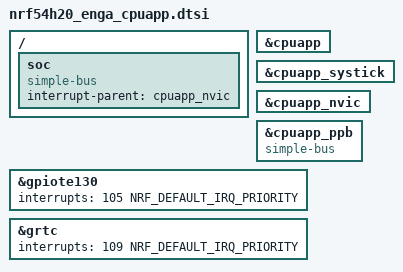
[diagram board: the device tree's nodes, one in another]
/*
 * Copyright (c) 2024 Nordic Semiconductor ASA
 *
 * SPDX-License-Identifier: Apache-2.0
 */

#include <nordic/nrf54h20_enga.dtsi>

cpu: &cpuapp {};
systick: &cpuapp_systick {};
nvic: &cpuapp_nvic {};

/delete-node/ &cpuppr;
/delete-node/ &cpurad;
/delete-node/ &cpurad_peripherals;
/delete-node/ &cpurad_ppb;
/delete-node/ &cpurad_ram0;

/ {
	soc {
		compatible = "simple-bus";
		interrupt-parent = <&cpuapp_nvic>;
		ranges;
	};
};

&cpuapp_ppb {
	compatible = "simple-bus";
	ranges;
};

&gpiote130 {
	interrupts = <105 NRF_DEFAULT_IRQ_PRIORITY>;
};

&grtc {
	interrupts = <109 NRF_DEFAULT_IRQ_PRIORITY>;
};
